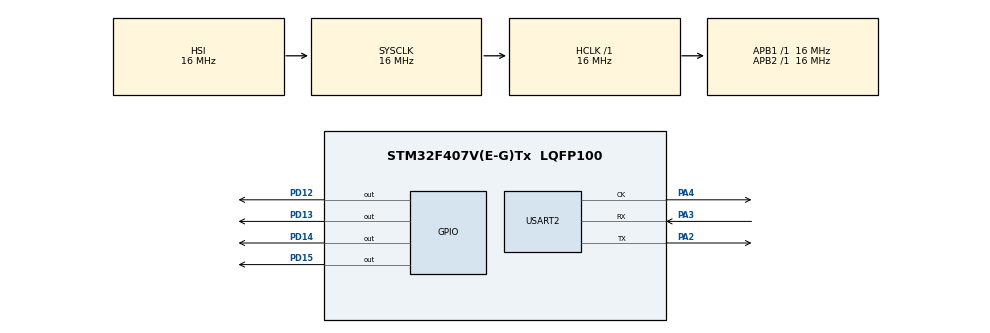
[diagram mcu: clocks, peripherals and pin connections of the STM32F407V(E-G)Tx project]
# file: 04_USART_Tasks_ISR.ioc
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FREERTOS.Tasks01=defaultTask,24,128,StartDefaultTask,Default,NULL,Dynamic,NULL,NULL
FREERTOS.configUSE_NEWLIB_REENTRANT=1
Mcu.Family=STM32F4
Mcu.Name=STM32F407V(E-G)Tx
Mcu.Package=LQFP100
NVIC.PriorityGroup=NVIC_PRIORITYGROUP_4
NVIC.TIM1_UP_TIM10_IRQn=true\:15\:0\:false\:false\:true\:false\:false\:true\:true
NVIC.TimeBase=TIM1_UP_TIM10_IRQn
NVIC.TimeBaseIP=TIM1
NVIC.USART2_IRQn=true\:5\:0\:false\:false\:true\:true\:true\:true\:true
PA13.Mode=Serial_Wire
PA13.Signal=SYS_JTMS-SWDIO
PA14.Mode=Serial_Wire
PA14.Signal=SYS_JTCK-SWCLK
PA2.Mode=Synchronous
PA2.Signal=USART2_TX
PA3.Mode=Synchronous
PA3.Signal=USART2_RX
PA4.Mode=Synchronous
PA4.Signal=USART2_CK
PD12.Signal=GPIO_Output
PD13.Signal=GPIO_Output
PD14.Signal=GPIO_Output
PD15.Signal=GPIO_Output
ProjectManager.HeapSize=0x200
ProjectManager.StackSize=0x400
ProjectManager.TargetToolchain=STM32CubeIDE
RCC.AHBFreq_Value=16000000
RCC.APB1Freq_Value=16000000
RCC.APB2Freq_Value=16000000
RCC.CortexFreq_Value=16000000
RCC.HSE_VALUE=25000000
RCC.HSI_VALUE=16000000
RCC.LSE_VALUE=32768
RCC.SYSCLKFreq_VALUE=16000000
RCC.VCOOutputFreq_Value=192000000
USART2.VirtualMode=VM_SYNC
VP_FREERTOS_VS_CMSIS_V2.Mode=CMSIS_V2
VP_SYS_VS_tim1.Mode=TIM1
board=custom

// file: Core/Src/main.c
/* USER CODE BEGIN Header */
/**
  ******************************************************************************
  * @file           : main.c
  * @brief          : Main program body
  ******************************************************************************
  * @attention
  *
  * Copyright (c) 2025 STMicroelectronics.
  * All rights reserved.
  *
  * This software is licensed under terms that can be found in the LICENSE file
  * in the root directory of this software component.
  * If no LICENSE file comes with this software, it is provided AS-IS.
  *
  ******************************************************************************
  */
/* USER CODE END Header */
#include "main.h"
#include "cmsis_os.h"

/* USER CODE BEGIN Includes */
#include "uart_comm.h"
/* USER CODE END Includes */

USART_HandleTypeDef husart2;

/* Definitions for defaultTask */
osThreadId_t defaultTaskHandle;
const osThreadAttr_t defaultTask_attributes = {
  .name = "defaultTask",
  .stack_size = 128 * 4,
  .priority = (osPriority_t) osPriorityNormal,
};

void SystemClock_Config(void);
static void MX_GPIO_Init(void);
static void MX_USART2_Init(void);
void StartDefaultTask(void *argument);

int main(void)
{

  /* MCU Configuration--------------------------------------------------------*/

  /* Reset of all peripherals, Initializes the Flash interface and the Systick. */
  HAL_Init();

  /* USER CODE BEGIN Init */
  /* Enable the UART interrupt */
  __HAL_USART_ENABLE_IT(&husart2, USART_IT_RXNE);
  HAL_NVIC_SetPriority(USART2_IRQn, 5, 0);
  HAL_NVIC_EnableIRQ(USART2_IRQn);

  /* USER CODE END Init */

  /* Configure the system clock */
  SystemClock_Config();

  /* Initialize all configured peripherals */
  MX_GPIO_Init();
  MX_USART2_Init();

  /* Init scheduler */
  osKernelInitialize();

  /* Create the thread(s) */
  /* creation of defaultTask */

  /* USER CODE BEGIN RTOS_THREADS */
  /* add threads, ... */
  USART_Example();
  /* USER CODE END RTOS_THREADS */

  /* Start scheduler */
  osKernelStart();

  /* We should never get here as control is now taken by the scheduler */

  /* Infinite loop */
  while (1)
  {

  }
}

void SystemClock_Config(void)
{
  RCC_OscInitTypeDef RCC_OscInitStruct = {0};
  RCC_ClkInitTypeDef RCC_ClkInitStruct = {0};

  /** Configure the main internal regulator output voltage
  */
  __HAL_RCC_PWR_CLK_ENABLE();
  __HAL_PWR_VOLTAGESCALING_CONFIG(PWR_REGULATOR_VOLTAGE_SCALE1);

  /** Initializes the RCC Oscillators according to the specified parameters
  * in the RCC_OscInitTypeDef structure.
  */
  RCC_OscInitStruct.OscillatorType = RCC_OSCILLATORTYPE_HSI;
  RCC_OscInitStruct.HSIState = RCC_HSI_ON;
  RCC_OscInitStruct.HSICalibrationValue = RCC_HSICALIBRATION_DEFAULT;
  RCC_OscInitStruct.PLL.PLLState = RCC_PLL_NONE;
  if (HAL_RCC_OscConfig(&RCC_OscInitStruct) != HAL_OK)
  {
    Error_Handler();
  }

  /** Initializes the CPU, AHB and APB buses clocks
  */
  RCC_ClkInitStruct.ClockType = RCC_CLOCKTYPE_HCLK|RCC_CLOCKTYPE_SYSCLK
                              |RCC_CLOCKTYPE_PCLK1|RCC_CLOCKTYPE_PCLK2;
  RCC_ClkInitStruct.SYSCLKSource = RCC_SYSCLKSOURCE_HSI;
  RCC_ClkInitStruct.AHBCLKDivider = RCC_SYSCLK_DIV1;
  RCC_ClkInitStruct.APB1CLKDivider = RCC_HCLK_DIV1;
  RCC_ClkInitStruct.APB2CLKDivider = RCC_HCLK_DIV1;

  if (HAL_RCC_ClockConfig(&RCC_ClkInitStruct, FLASH_LATENCY_0) != HAL_OK)
  {
    Error_Handler();
  }
}

static void MX_USART2_Init(void)
{

  husart2.Instance = USART2;
  husart2.Init.BaudRate = 115200;
  husart2.Init.WordLength = USART_WORDLENGTH_8B;
  husart2.Init.StopBits = USART_STOPBITS_1;
  husart2.Init.Parity = USART_PARITY_NONE;
  husart2.Init.Mode = USART_MODE_TX_RX;
  husart2.Init.CLKPolarity = USART_POLARITY_LOW;
  husart2.Init.CLKPhase = USART_PHASE_1EDGE;
  husart2.Init.CLKLastBit = USART_LASTBIT_DISABLE;
  if (HAL_USART_Init(&husart2) != HAL_OK)
  {
    Error_Handler();
  }

}

static void MX_GPIO_Init(void)
{
  GPIO_InitTypeDef GPIO_InitStruct = {0};

  /* GPIO Ports Clock Enable */
  __HAL_RCC_GPIOA_CLK_ENABLE();
  __HAL_RCC_GPIOD_CLK_ENABLE();

  /*Configure GPIO pin Output Level */
  HAL_GPIO_WritePin(GPIOD, GPIO_PIN_12|GPIO_PIN_13|GPIO_PIN_14|GPIO_PIN_15, GPIO_PIN_RESET);

  /*Configure GPIO pins : PD12 PD13 PD14 PD15 */
  GPIO_InitStruct.Pin = GPIO_PIN_12|GPIO_PIN_13|GPIO_PIN_14|GPIO_PIN_15;
  GPIO_InitStruct.Mode = GPIO_MODE_OUTPUT_PP;
  GPIO_InitStruct.Pull = GPIO_NOPULL;
  GPIO_InitStruct.Speed = GPIO_SPEED_FREQ_LOW;
  HAL_GPIO_Init(GPIOD, &GPIO_InitStruct);

}

void StartDefaultTask(void *argument)
{
  for(;;)
  {
    osDelay(1);
  }
}

void HAL_TIM_PeriodElapsedCallback(TIM_HandleTypeDef *htim)
{
  if (htim->Instance == TIM1)
  {
    HAL_IncTick();
  }
}

void Error_Handler(void)
{
  __disable_irq();
  while (1)
  {
  }
}
